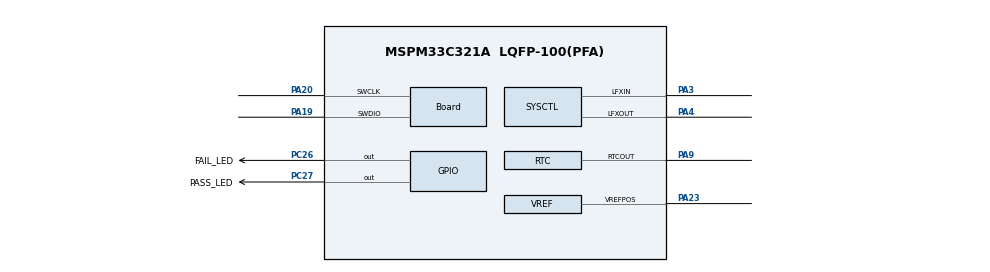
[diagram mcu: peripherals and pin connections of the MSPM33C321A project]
//@cliArgs --device "MSPM33C321A" --package "LQFP-100(PFA)" --part "Default"
//@v2CliArgs --device "MSPM33C321A" --package "LQFP-100(PFA)"
// @cliArgs --board /ti/boards/LP_MSPM33C321A --rtos nortos


/**
 * Import the modules used in this configuration.
 */
const GPIO   = scripting.addModule("/ti/driverlib/GPIO", {}, false);
const GPIO1  = GPIO.addInstance();
const HSADC  = scripting.addModule("/ti/driverlib/HSADC", {}, false);
const HSADC1 = HSADC.addInstance();
const RTC    = scripting.addModule("/ti/driverlib/RTC");
const SYSCTL = scripting.addModule("/ti/driverlib/SYSCTL");
const VREF   = scripting.addModule("/ti/driverlib/VREF");

/**
 * Write custom configuration values to the imported modules.
 */
GPIO1.$name                               = "GPIO_LEDS";
GPIO1.associatedPins.create(2);
GPIO1.associatedPins[0].$name             = "PASS_LED";
GPIO1.associatedPins[0].launchPadShortcut = "LED2GreenEn";
GPIO1.associatedPins[0].pin.$assign       = "PC27";
GPIO1.associatedPins[1].$name             = "FAIL_LED";
GPIO1.associatedPins[1].launchPadShortcut = "LED2RedEn";
GPIO1.associatedPins[1].pin.$assign       = "PC26";

const Board                       = scripting.addModule("/ti/driverlib/Board", {}, false);
Board.peripheral.$assign          = "DEBUGSS";
Board.peripheral.swclkPin.$assign = "PA20";
Board.peripheral.swdioPin.$assign = "PA19";

HSADC1.$name              = "HSADC0";
HSADC1.adcClockPrescaler  = "DL_HSADC_CLOCK_DIVIDE_8_0";
HSADC1.enabledSOCs        = ["ADC_SOC_NUMBER0"];
HSADC1.soc0Channel        = "ADC_CH_ADCIN_11";
HSADC1.enabledInts        = ["ADC_INT_NUMBER_1"];
HSADC1.enableInterrupt1   = true;
HSADC1.enabledSEQs        = ["ADC_SEQ_NUMBER1"];
HSADC1.seq1Enable         = true;
HSADC1.seq1SampleWindow   = 200;
HSADC1.peripheral.$assign = "ADC0";

RTC.calSec                       = 45;
RTC.calMin                       = 32;
RTC.calHour                      = 10;
RTC.calDOW                       = "1";
RTC.calDOM                       = 5;
RTC.calMonth                     = "4";
RTC.calYear                      = 2021;
RTC.offsetCalFreq                = "512";
RTC.peripheral.$assign           = "LFSS";
RTC.peripheral.rtcOutPin.$assign = "PA9";

SYSCTL.LFCLKSource                  = "LFXT";
SYSCTL.peripheral.$assign           = "SYSCTL";
SYSCTL.peripheral.lfxInPin.$assign  = "PA3";
SYSCTL.peripheral.lfxOutPin.$assign = "PA4";

VREF.basicIntVolt                  = "DL_VREF_BUFCONFIG_OUTPUT_2_5V";
VREF.advClockConfigEnable          = true;
VREF.peripheral.$assign            = "VREF";
VREF.peripheral.vrefPosPin.$assign = "PA23";
VREF.vrefPosPinConfig.$name        = "ti_driverlib_gpio_GPIOPinGeneric0";

const ProjectConfig              = scripting.addModule("/ti/project_config/ProjectConfig", {}, false);
ProjectConfig.migrationCondition = true;

ProjectConfig.genLinker  = true;
ProjectConfig.genStartup = true;
ProjectConfig.genOpts    = true;
ProjectConfig.genLibs    = true;
